# STM32G564 register map
File version: 2.0.0
CPU: CM33 r0p4, little endian, MPU, FPU, 4 interrupt priority bits
Registers are 32-bit, read-write, reset 0x0 unless marked. A register's access mark holds for its fields unless they carry their own. Offsets are from the block's base; [hi:lo] are bit positions; {n}, {i} and the like mark numbered series; 'fields as' and 'values as' point back to an identical list.

## PWR — PWR register block
Base 0x44020800
Same registers: PWR_S 0x54020800
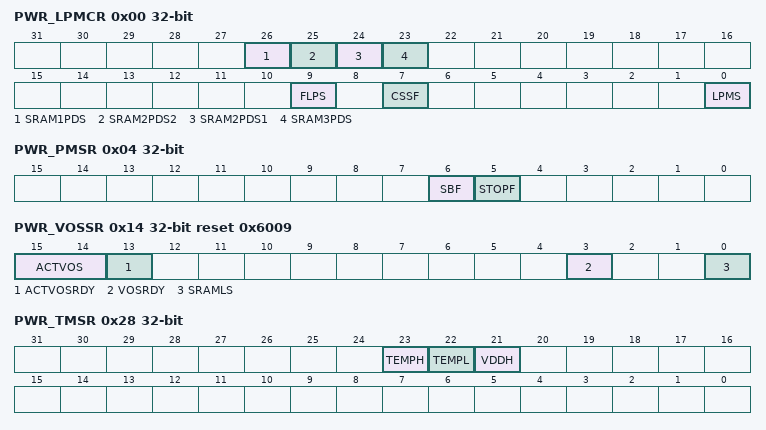
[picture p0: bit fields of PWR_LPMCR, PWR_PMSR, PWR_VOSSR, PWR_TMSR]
0x00 PWR_LPMCR — PWR low power mode control register
  [26] SRAM1PDS — AHB SRAM1 power-down in Stop mode
    0=AHB RAM1 content is kept in Stop mode; 1=AHB RAM1 content is lost in Stop mode
  [25] SRAM2PDS2 — AHB SRAM2 page 2 power-down in Stop mode.
    0=AHB RAM2 page 2 content is kept in Stop mode; 1=AHB RAM2 page 2 content is lost in Stop mode
  [24] SRAM2PDS1 — AHB SRAM2 page 1 power-down in Stop mode.
    0=AHB RAM2 page 1 content is kept in Stop mode; 1=AHB RAM2 page 1 content is lost in Stop mode
  [23] SRAM3PDS — AHB SRAM3 power-down in Stop mode.
    0=AHB RAM3 content is kept in Stop mode; 1=AHB RAM3 content is lost in Stop mode
  [9] FLPS — flash memory low-power mode in Stop mode
    0=flash memory remains in normal mode when the system enters Stop mode (quickrestart time); 1=flash memory enters low-power mode when the system enters Stop mode(low-power consumption)
  [7] CSSF — clear Standby and Stop flags (always read as 0)
    0=no effect; 1=STOPF and SBF flags cleared
  [0] LPMS — low-power mode selection
    0=keeps Stop mode when entering DeepSleep; 1=allows Standby mode when entering DeepSleep
0x04 PWR_PMSR ro — PWR status register
  [6] SBF — System standby flag
    0=system has not been in Standby mode; 1=system has been in Standby mode
  [5] STOPF — Stop flag
    0=system has not been in Stop mode; 1=system has been in Stop mode
0x10 PWR_VOSCR reset 0x10 — PWR voltage scaling control register
  [5:4] VOS — voltage scaling selection according to performance
    1=range 2 (VOS2, default): Low-power range; 2=range 1: Medium-performance range; 3=range 0: High-performance range
0x14 PWR_VOSSR ro reset 0x6009 — PWR voltage scaling status register
  [15:14] ACTVOS — Current voltage scaling range
    1=VOS2 (lowest power); 2=VOS1; 3=VOS0 (highest frequency)
  [13] ACTVOSRDY — Current VOS voltage level ready
    0=VCORE is above or below the current voltage scaling provided by ACTVOS[1:0]; 1=VCORE is equal to the current voltage scaling provided by ACTVOS[1:0]
  [3] VOSRDY — Ready bit for VCORE voltage scaling output selection
    0=Not ready, voltage level below VOS selected level; 1=Ready, voltage level at or above VOS selected level
  [0] SRAMLS — SRAM memories operation at low speed
    0=SRAMs operating at high speed (VOS1 or VOS0 voltage scaling); 1=SRAMs operating at low speed (VOS2 voltage scaling)
0x20 PWR_TMCR — PWR tamper monitoring control register
  [1] MONEN — VDD voltage and temperature monitoring enable
    0=VDD voltage and temperature monitoring disabled; 1=VDD voltage and temperature monitoring enabled
0x24 PWR_RTCCR — PWR RTC domain control register
  [0] DRTCP — Disable RTC domain write protection
    0=Write access to RTC domain disabled; 1=Write access to RTC domain enabled
0x28 PWR_TMSR ro — PWR tamper monitoring status register
  [23] TEMPH — temperature level monitoring versus high threshold
    0=temperature below high threshold level; 1=temperature equal or above high threshold level
  [22] TEMPL — temperature level monitoring versus low threshold
    0=temperature above low threshold level; 1=temperature equal or below low threshold level
  [21] VDDH — VDD voltage level monitoring versus high threshold
    0=VDD voltage level below high threshold level; 1=VDD voltage level equal or above high threshold level
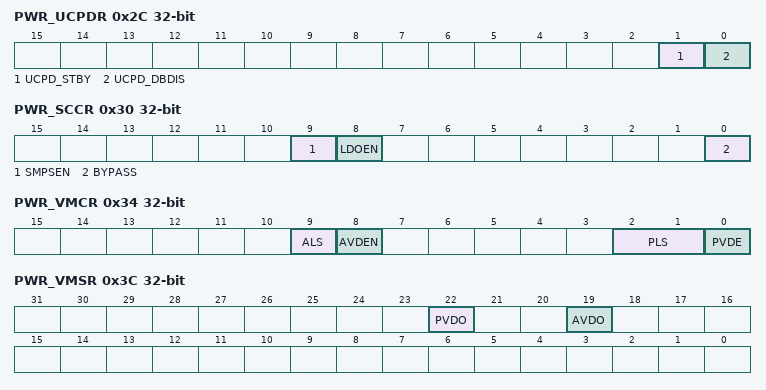
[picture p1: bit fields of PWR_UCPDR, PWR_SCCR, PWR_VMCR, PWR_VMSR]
0x2C PWR_UCPDR — PWR USB Type-C power delivery register
  [1] UCPD_STBY — USB Type-c and Power delivery Standby mode
  [0] UCPD_DBDIS — USB Type-C and power delivery dead battery disable
    0=Enable USB Type-C dead battery pull-down behavior on UCPDx_CC1 and UCPDx_CC2pins; 1=Disable USB Type-C dead battery pull-down behavior on UCPDx_CC1 and UCPDx_CC2pins
0x30 PWR_SCCR rw-once (reset mask 0xFFFFF0F0) — PWR supply configuration control register
  [9] SMPSEN ro — SMPS enable
  [8] LDOEN ro — LDO enable
  [0] BYPASS — power management unit bypass
    0=Power management unit normal operation; 1=Power management unit bypassed
0x34 PWR_VMCR — PWR voltage monitor control register
  [9] ALS — analog voltage detector (AVD) level selection
    0=AVD level0; 1=AVD level1
  [8] AVDEN — peripheral voltage monitor on VDD voltage enable
    0=peripheral voltage monitor on VDD voltage disabled; 1=peripheral voltage monitor on VDD voltage enabled
  [2:1] PLS — programmable voltage detector (PVD) level selection
    0=PVD level0; 1=PVD level1; 3=PVD_IN pin
  [0] PVDE — PVD enable
    0=PVD disabled; 1=PVD enabled
0x38 PWR_USBSCR — PWR USB supply control register
  [25] USB33SV — USB supply valid
    0=VDD voltage is not valid for USB usage; 1=VDD voltage is valid for USB usage
0x3C PWR_VMSR ro (reset mask 0xFF0FFFFF) — PWR voltage monitor status register
  [22] PVDO — programmable voltage detector output
    0=VDD voltage is equal or higher than the PVD threshold selected through the PLS[1:0] bits; 1=VDD voltage is lower than the PVD threshold selected through the PLS[1:0] bits
  [19] AVDO — analog voltage detector output on VDD voltage
    0=VDD voltage is equal or higher than the AVD threshold selected with the ALS bit; 1=VDD voltage is lower than the AVD threshold selected with the ALS bit
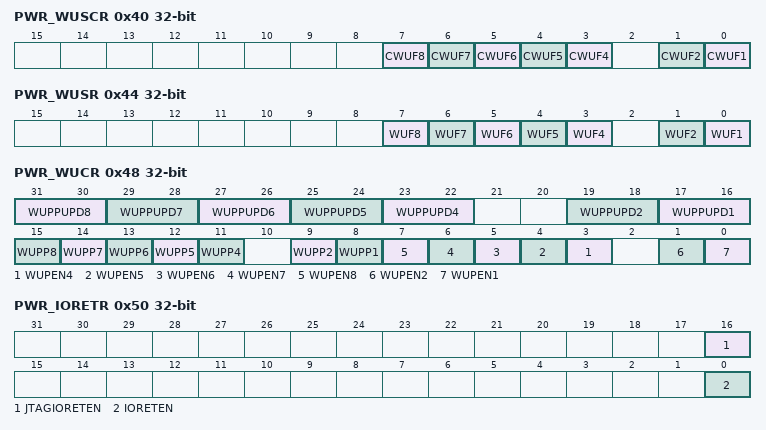
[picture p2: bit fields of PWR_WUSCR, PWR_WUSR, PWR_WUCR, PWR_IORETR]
0x40 PWR_WUSCR wo — PWR wake-up status clear register
  [all] fields
    0=no effect; 1=writing 1 clears the WUFx wake-up pin flag (bit is cleared to 0 by hardware)
  [n-1] CWUF{n} (n=4..8) — clear wake-up pin flag for WUFx (x=8 to4, 2 to 1)
  [1] CWUF2 — clear wake-up pin flag for WUFx (x=8 to4, 2 to 1)
  [0] CWUF1 — clear wake-up pin flag for WUFx (x=8 to4, 2 to 1)
0x44 PWR_WUSR ro — PWR wake-up status register
  [all] fields
    0=no wake-up event occurred; 1=wake-up event received from WUFx pin
  [n-1] WUF{n} (n=4..8) — wake-up pin WUFx flag (x = 8 to 4, 2 to 1)
  [1] WUF2 — wake-up pin WUFx flag (x = 8 to 4, 2 to 1)
  [0] WUF1 — wake-up pin WUFx flag (x = 8 to 4, 2 to 1)
0x48 PWR_WUCR — PWR wake-up configuration register
  [2n+15:2n+14] WUPPUPD{n} (n=4..8) — wake-up pin pull configuration for WKUPx (x=8 to 4, 2 to 1)
    0=no pull-up; 1=pull-up; 2=pull-down
  [19:18] WUPPUPD2 — wake-up pin pull configuration for WKUPx (x=8 to 4, 2 to 1)
    0=no pull-up; 1=pull-up; 2=pull-down
  [17:16] WUPPUPD1 — wake-up pin pull configuration for WKUPx (x=8 to 4, 2 to 1)
    0=no pull-up; 1=pull-up; 2=pull-down
  [n+7] WUPP{n} (n=4..8) — wake-up pin polarity bit for WUPx (x=8 to 4, 2 to 1)
    0=detection on high level (rising edge); 1=detection on low level (falling edge)
  [9] WUPP2 — wake-up pin polarity bit for WUPx (x=8 to 4, 2 to 1)
    values as WUPP4
  [8] WUPP1 — wake-up pin polarity bit for WUPx (x=8 to 4, 2 to 1)
    values as WUPP4
  [n-1] WUPEN{n} (n=4..8) — enable wake-up pin WUPx (x=8 to 4, 2 to 1)
    0=an event on WUPx pin does not wake-up the system from Standby mode; 1=a rising or falling edge on WUPx pin wakes up the system from Standby mode
  [1] WUPEN2 — enable wake-up pin WUPx (x=8 to 4, 2 to 1)
    values as WUPEN4
  [0] WUPEN1 — enable wake-up pin WUPx (x=8 to 4, 2 to 1)
    values as WUPEN4
0x50 PWR_IORETR — PWR I/O retention register
  [16] JTAGIORETEN — JTAG IOs retention enable
    0=PA13, PA14, PA15, and PB4 IO Retention mode disabled; 1=PA13, PA14, PA15, and PB4 Retention mode enabled
  [0] IORETEN — IO retention enable
    0=IOs (except JTAG I/Os) Retention mode disabled; 1=IIOs (except JTAG I/Os) Retention mode enabled for all IOs except those that are functional in Standby mode
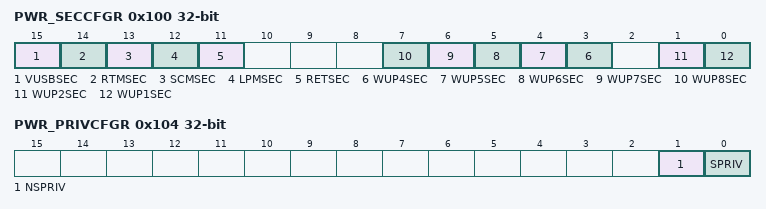
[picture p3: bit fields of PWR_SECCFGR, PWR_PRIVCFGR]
0x100 PWR_SECCFGR — PWR security configuration register
  [15] VUSBSEC — voltage USB secure protection
    0=PWR_USBSCR can be read and written with secure or nonsecure accesses; 1=PWR_USBSCR can be read and written only with secure accesses
  [14] RTMSEC — RTC domain and tamper monitoring secure protection
    0=PWR_TMCR and PWR_RTCCR can be read and written with secure or nonsecure accesses; 1=PWR_TMCR and PWR_RTCCR can be read and written only with secure accesses
  [13] SCMSEC — supply configuration and monitoring secure protection.
    0=PWR_SCCR and PWR_VMCR can be read and written with secure or nonsecure accesses; 1=PWR_SCCR and PWR_VMCR can be read and written only with secure accesses
  [12] LPMSEC — low-power modes secure protection
    0=PWR_LPMCR can be read and written with secure or nonsecure accesses; 1=PWR_LPMCR can be read and written only with secure accesses
  [11] RETSEC — retention secure protection
    0=PWR_IORETR can be read and written with secure or nonsecure accesses; 1=PWR_IORETR can be read and written only with secure accesses
  [n-1] WUP{n}SEC (n=4..8) — WUPx secure protection (x=8 to 4, 2 to 1)
    0=The bits related to the WKUPx wake-up pin in PWR_WUSCR and PWR_WUCR can be read and written with secure or nonsecure accesses; 1=The bits related to the WKUPx wake-up pin in PWR_WUSCR and PWR_WUCR can be read and written only with secure accesses
  [1] WUP2SEC — WUPx secure protection (x=8 to 4, 2 to 1)
    values as WUP4SEC
  [0] WUP1SEC — WUPx secure protection (x=8 to 4, 2 to 1)
    values as WUP4SEC
0x104 PWR_PRIVCFGR — PWR privilege configuration register
  [1] NSPRIV — PWR nonsecure functions privilege configuration
    0=Read and write to PWR nonsecure functions can be done by privileged or unprivileged accesses; 1=Read and write to PWR nonsecure functions can be done by privileged accesses only
  [0] SPRIV — PWR secure functions privilege configuration
    0=Read and write to PWR secure functions can be done by privileged or unprivileged accesses; 1=Read and write to PWR secure functions can be done by privileged accesses only
